# iorx62n register map
Registers from a debugger description file.
Registers are 8-bit, access not given, no defined reset value unless marked. A register's access mark holds for its fields unless they carry their own. Addresses are absolute; registers are grouped by the start of their names; lines under a group give offsets from that group; [hi:lo] are bit positions; {n}, {i} and the like mark numbered series; 'fields as' and 'values as' point back to an identical list; <NAME> marks a mode.

## SFR (part 1 of 3)
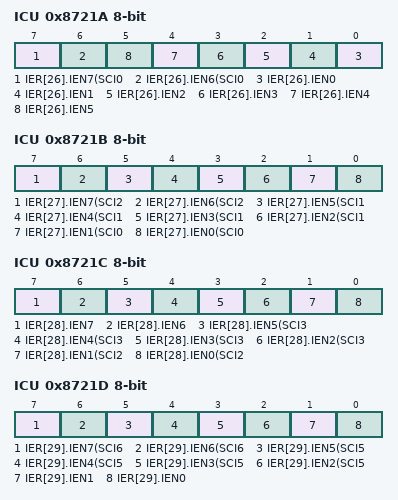
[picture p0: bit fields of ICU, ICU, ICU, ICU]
0x8721A ICU
  [7] IER[26].IEN7(SCI0,RXI0), [6] IER[26].IEN6(SCI0,ERI0), [n] IER[26].IEN{n} (n=0..5)
0x8721B ICU
  [7] IER[27].IEN7(SCI2,RXI2), [6] IER[27].IEN6(SCI2,ERI2), [5] IER[27].IEN5(SCI1,TEI1), [4] IER[27].IEN4(SCI1,TXI1), [3] IER[27].IEN3(SCI1,RXI1), [2] IER[27].IEN2(SCI1,ERI1), [1] IER[27].IEN1(SCI0,TEI0), [0] IER[27].IEN0(SCI0,TXI0)
0x8721C ICU
  [7] IER[28].IEN7, [6] IER[28].IEN6, [5] IER[28].IEN5(SCI3,TEI3), [4] IER[28].IEN4(SCI3,TXI3), [3] IER[28].IEN3(SCI3,RXI3), [2] IER[28].IEN2(SCI3,ERI3), [1] IER[28].IEN1(SCI2,TEI2), [0] IER[28].IEN0(SCI2,TXI2)
0x8721D ICU
  [7] IER[29].IEN7(SCI6,RXI6), [6] IER[29].IEN6(SCI6,ERI6), [5] IER[29].IEN5(SCI5,TEI5), [4] IER[29].IEN4(SCI5,TXI5), [3] IER[29].IEN3(SCI5,RXI5), [2] IER[29].IEN2(SCI5,ERI5), [1] IER[29].IEN1, [0] IER[29].IEN0
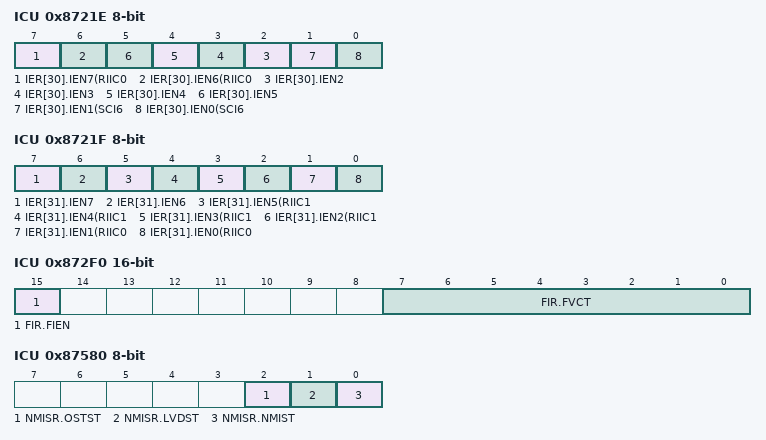
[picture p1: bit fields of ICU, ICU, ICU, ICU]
0x8721E ICU
  [7] IER[30].IEN7(RIIC0,ICRXI0), [6] IER[30].IEN6(RIIC0,ICEEI0), [n] IER[30].IEN{n} (n=2..5), [1] IER[30].IEN1(SCI6,TEI6), [0] IER[30].IEN0(SCI6,TXI6)
0x8721F ICU
  [7] IER[31].IEN7, [6] IER[31].IEN6, [5] IER[31].IEN5(RIIC1,ICTEI1), [4] IER[31].IEN4(RIIC1,ICTXI1), [3] IER[31].IEN3(RIIC1,ICRXI1), [2] IER[31].IEN2(RIIC1,ICEEI1), [1] IER[31].IEN1(RIIC0,ICTEI0), [0] IER[31].IEN0(RIIC0,ICTXI0)
0x872E0 ICU
  [0] SWINTR.SWINT
0x872F0 ICU 16-bit
  [15] FIR.FIEN, [7:0] FIR.FVCT
0x87300 ICU
  [3:0] IPR[0](BSC,BUSERR).IPR
0x87301 ICU
  [3:0] IPR[1](FCU,FIFERR).IPR
0x87302 ICU
  [3:0] IPR[2](FCU,FRDYI).IPR
0x87303 ICU
  [3:0] IPR[3](ICU,SWINT).IPR
0x87304 ICU
  [3:0] IPR[4](CMT0,CMI0).IPR
0x87305 ICU
  [3:0] IPR[5](CMT1,CMI1).IPR
0x87306 ICU
  [3:0] IPR[6](CMT2,CMI2).IPR
0x87307 ICU
  [3:0] IPR[7](CMT3,CMI3).IPR
0x87308 ICU
  [3:0] IPR[8](ETHER,EINT).IPR
0x87309 ICU
  [3:0] IPR[9].IPR
0x8730A ICU
  [3:0] IPR[10].IPR
0x8730B ICU
  [3:0] IPR[11].IPR
0x8730C ICU
  [3:0] IPR[12](USB0,D0FIFO0).IPR
0x8730D ICU
  [3:0] IPR[13](USB0,D1FIFO0).IPR
0x8730E ICU
  [3:0] IPR[14](USB0,USBI0).IPR
0x8730F ICU
  [3:0] IPR[15].IPR
0x87310 ICU
  [3:0] IPR[16](USB1,D0FIFO1).IPR
0x87311 ICU
  [3:0] IPR[17](USB1,D1FIFO1).IPR
0x87312 ICU
  [3:0] IPR[18](USB1,USBI1).IPR
0x87313 ICU
  [3:0] IPR[19].IPR
0x87314 ICU
  [3:0] IPR[20](RSPI0,SPEI0...).IPR
0x87315 ICU
  [3:0] IPR[21](RSPI1,SPEI1...).IPR
0x87316 ICU
  [3:0] IPR[22].IPR
0x87317 ICU
  [3:0] IPR[23].IPR
0x87318 ICU
  [3:0] IPR[24](CAN0,ERS0...).IPR
0x87319 ICU
  [3:0] IPR[25].IPR
0x8731A ICU
  [3:0] IPR[26].IPR
0x8731B ICU
  [3:0] IPR[27].IPR
0x8731C ICU
  [3:0] IPR[28].IPR
0x8731D ICU
  [3:0] IPR[29].IPR
0x8731E ICU
  [3:0] IPR[30](RTC,PRD).IPR
0x8731F ICU
  [3:0] IPR[31](RTC,CUP).IPR
0x87320 ICU
  [3:0] IPR[32](ICU,IRQ0).IPR
0x87321 ICU
  [3:0] IPR[33](ICU,IRQ1).IPR
0x87322 ICU
  [3:0] IPR[34](ICU,IRQ2).IPR
0x87323 ICU
  [3:0] IPR[35](ICU,IRQ3).IPR
0x87324 ICU
  [3:0] IPR[36](ICU,IRQ4).IPR
0x87325 ICU
  [3:0] IPR[37](ICU,IRQ5).IPR
0x87326 ICU
  [3:0] IPR[38](ICU,IRQ6).IPR
0x87327 ICU
  [3:0] IPR[39](ICU,IRQ7).IPR
0x87328 ICU
  [3:0] IPR[40](ICU,IRQ8).IPR
0x87329 ICU
  [3:0] IPR[41](ICU,IRQ9).IPR
0x8732A ICU
  [3:0] IPR[42](ICU,IRQ10).IPR
0x8732B ICU
  [3:0] IPR[43](ICU,IRQ11).IPR
0x8732C ICU
  [3:0] IPR[44](ICU,IRQ12).IPR
0x8732D ICU
  [3:0] IPR[45](ICU,IRQ13).IPR
0x8732E ICU
  [3:0] IPR[46](ICU,IRQ14).IPR
0x8732F ICU
  [3:0] IPR[47](ICU,IRQ15).IPR
0x87330 ICU
  [3:0] IPR[48].IPR
0x87331 ICU
  [3:0] IPR[49].IPR
0x87332 ICU
  [3:0] IPR[50].IPR
0x87333 ICU
  [3:0] IPR[51].IPR
0x87334 ICU
  [3:0] IPR[52].IPR
0x87335 ICU
  [3:0] IPR[53].IPR
0x87336 ICU
  [3:0] IPR[54].IPR
0x87337 ICU
  [3:0] IPR[55].IPR
0x87338 ICU
  [3:0] IPR[56].IPR
0x87339 ICU
  [3:0] IPR[57].IPR
0x8733A ICU
  [3:0] IPR[58](USB,USBR0).IPR
0x8733B ICU
  [3:0] IPR[59](USB,USBR1).IPR
0x8733C ICU
  [3:0] IPR[60](RTC,ALM).IPR
0x8733D ICU
  [3:0] IPR[61].IPR
0x8733E ICU
  [3:0] IPR[62].IPR
0x8733F ICU
  [3:0] IPR[63].IPR
0x87340 ICU
  [3:0] IPR[64](WDT,WOVI).IPR
0x87341 ICU
  [3:0] IPR[65].IPR
0x87342 ICU
  [3:0] IPR[66].IPR
0x87343 ICU
  [3:0] IPR[67].IPR
0x87344 ICU
  [3:0] IPR[68](AD0,ADI0).IPR
0x87345 ICU
  [3:0] IPR[69](AD1,ADI1).IPR
0x87346 ICU
  [3:0] IPR[70].IPR
0x87347 ICU
  [3:0] IPR[71].IPR
0x87348 ICU
  [3:0] IPR[72](S12AD,ADI).IPR
0x87349 ICU
  [3:0] IPR[73].IPR
0x8734A ICU
  [3:0] IPR[74].IPR
0x8734B ICU
  [3:0] IPR[75].IPR
0x8734C ICU
  [3:0] IPR[76].IPR
0x8734D ICU
  [3:0] IPR[77].IPR
0x8734E ICU
  [3:0] IPR[78].IPR
0x8734F ICU
  [3:0] IPR[79].IPR
0x87350 ICU
  [3:0] IPR[80].IPR
0x87351 ICU
  [3:0] IPR[81](MTU0,TGIA0...).IPR
0x87352 ICU
  [3:0] IPR[82](MTU0,TCIV0...).IPR
0x87353 ICU
  [3:0] IPR[83](MTU1,TGIA1...).IPR
0x87354 ICU
  [3:0] IPR[84](MTU1,TCIV1...).IPR
0x87355 ICU
  [3:0] IPR[85](MTU2,TGIA2...).IPR
0x87356 ICU
  [3:0] IPR[86](MTU2,TCIV2...).IPR
0x87357 ICU
  [3:0] IPR[87](MTU3,TGIA3...).IPR
0x87358 ICU
  [3:0] IPR[88](MTU3,TCIV3).IPR
0x87359 ICU
  [3:0] IPR[89](MTU4,TGIA4...).IPR
0x8735A ICU
  [3:0] IPR[90](MTU4,TCIV4).IPR
0x8735B ICU
  [3:0] IPR[91](MTU5,TGIU5...).IPR
0x8735C ICU
  [3:0] IPR[92](MTU6,TGIA6...).IPR
0x8735D ICU
  [3:0] IPR[93](MTU6,TCIV6...).IPR
0x8735E ICU
  [3:0] IPR[94](MTU7,TGIA7...).IPR
0x8735F ICU
  [3:0] IPR[95](MTU7,TCIV7...).IPR
0x87360 ICU
  [3:0] IPR[96](MTU8,TGIA8...).IPR
0x87361 ICU
  [3:0] IPR[97](MTU8,TCIV8...).IPR
0x87362 ICU
  [3:0] IPR[98](MTU9,TGIA9...).IPR
0x87363 ICU
  [3:0] IPR[99](MTU9,TCIV9).IPR
0x87364 ICU
  [3:0] IPR[100](MTU10,TGIA10...).IPR
0x87365 ICU
  [3:0] IPR[101](MTU10,TCIV10).IPR
0x87366 ICU
  [3:0] IPR[102](MTU11,TGIU11...).IPR
0x87367 ICU
  [3:0] IPR[103](POE,OEI1...).IPR
0x87368 ICU
  [3:0] IPR[104](TMR0,CMIA0...).IPR
0x87369 ICU
  [3:0] IPR[105](TMR1,CMIA1...).IPR
0x8736A ICU
  [3:0] IPR[106](TMR2,CMIA2...).IPR
0x8736B ICU
  [3:0] IPR[107](TMR3,CMIA3...).IPR
0x8736C ICU
  [3:0] IPR[108].IPR
0x8736D ICU
  [3:0] IPR[109].IPR
0x8736E ICU
  [3:0] IPR[110].IPR
0x8736F ICU
  [3:0] IPR[111].IPR
0x87370 ICU
  [3:0] IPR[112](DMAC,DMAC0I).IPR
0x87371 ICU
  [3:0] IPR[113](DMAC,DMAC1I).IPR
0x87372 ICU
  [3:0] IPR[114](DMAC,DMAC2I).IPR
0x87373 ICU
  [3:0] IPR[115](DMAC,DMAC3I).IPR
0x87374 ICU
  [3:0] IPR[116](EXDMAC,EXDMAC0I).IPR
0x87375 ICU
  [3:0] IPR[117](EXDMAC,EXDMAC1I).IPR
0x87376 ICU
  [3:0] IPR[118].IPR
0x87377 ICU
  [3:0] IPR[119].IPR
0x87378 ICU
  [3:0] IPR[120].IPR
0x87379 ICU
  [3:0] IPR[121].IPR
0x8737A ICU
  [3:0] IPR[122].IPR
0x8737B ICU
  [3:0] IPR[123].IPR
0x8737C ICU
  [3:0] IPR[124].IPR
0x8737D ICU
  [3:0] IPR[125].IPR
0x8737E ICU
  [3:0] IPR[126].IPR
0x8737F ICU
  [3:0] IPR[127].IPR
0x87380 ICU
  [3:0] IPR[128](SCI0,ERI0...).IPR
0x87381 ICU
  [3:0] IPR[129](SCI1,ERI1...).IPR
0x87382 ICU
  [3:0] IPR[130](SCI2,ERI2...).IPR
0x87383 ICU
  [3:0] IPR[131](SCI3,ERI3...).IPR
0x87384 ICU
  [3:0] IPR[132].IPR
0x87385 ICU
  [3:0] IPR[133](SCI5,ERI5...).IPR
0x87386 ICU
  [3:0] IPR[134](SCI6,ERI6...).IPR
0x87387 ICU
  [3:0] IPR[135].IPR
0x87388 ICU
  [3:0] IPR[136](RIIC0,ICEEI0).IPR
0x87389 ICU
  [3:0] IPR[137](RIIC0,ICRXI0).IPR
0x8738A ICU
  [3:0] IPR[138](RIIC0,ICTXI0).IPR
0x8738B ICU
  [3:0] IPR[139](RIIC0,ICTEI0).IPR
0x8738C ICU
  [3:0] IPR[140](RIIC1,ICEEI1).IPR
0x8738D ICU
  [3:0] IPR[141](RIIC1,ICRXI1).IPR
0x8738E ICU
  [3:0] IPR[142](RIIC1,ICTXI1).IPR
0x8738F ICU
  [3:0] IPR[143](RIIC1,ICTEI1).IPR
0x87500 ICU
  [3:2] IRQCR[0].IRQMD
0x87501 ICU
  [3:2] IRQCR[1].IRQMD
0x87502 ICU
  [3:2] IRQCR[2].IRQMD
0x87503 ICU
  [3:2] IRQCR[3].IRQMD
0x87504 ICU
  [3:2] IRQCR[4].IRQMD
0x87505 ICU
  [3:2] IRQCR[5].IRQMD
0x87506 ICU
  [3:2] IRQCR[6].IRQMD
0x87507 ICU
  [3:2] IRQCR[7].IRQMD
0x87508 ICU
  [3:2] IRQCR[8].IRQMD
0x87509 ICU
  [3:2] IRQCR[9].IRQMD
0x8750A ICU
  [3:2] IRQCR[10].IRQMD
0x8750B ICU
  [3:2] IRQCR[11].IRQMD
0x8750C ICU
  [3:2] IRQCR[12].IRQMD
0x8750D ICU
  [3:2] IRQCR[13].IRQMD
0x8750E ICU
  [3:2] IRQCR[14].IRQMD
0x8750F ICU
  [3:2] IRQCR[15].IRQMD
0x87580 ICU
  [2] NMISR.OSTST, [1] NMISR.LVDST, [0] NMISR.NMIST
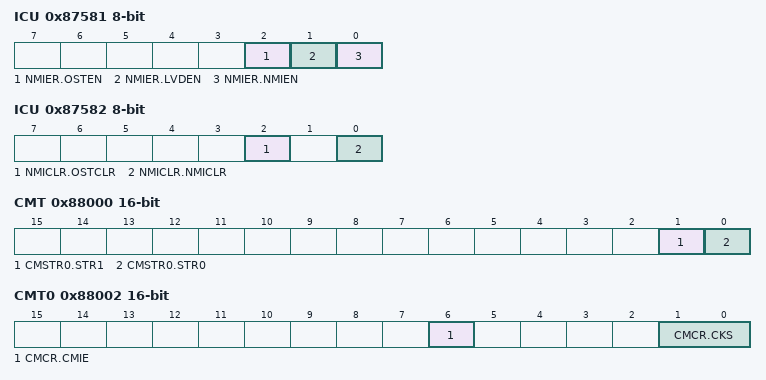
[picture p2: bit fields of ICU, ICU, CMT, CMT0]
0x87581 ICU
  [2] NMIER.OSTEN, [1] NMIER.LVDEN, [0] NMIER.NMIEN
0x87582 ICU
  [2] NMICLR.OSTCLR, [0] NMICLR.NMICLR
0x87583 ICU
  [3] NMICR.NMIMD
0x88000 CMT 16-bit
  [1] CMSTR0.STR1, [0] CMSTR0.STR0
0x88002 CMT0 16-bit
  [6] CMCR.CMIE, [1:0] CMCR.CKS
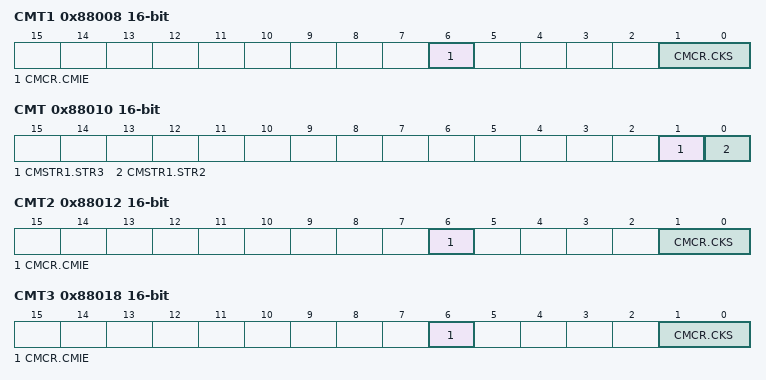
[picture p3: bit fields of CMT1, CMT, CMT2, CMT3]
0x88008 CMT1 16-bit
  [6] CMCR.CMIE, [1:0] CMCR.CKS
0x88010 CMT 16-bit
  [1] CMSTR1.STR3, [0] CMSTR1.STR2
0x88012 CMT2 16-bit
  [6] CMCR.CMIE, [1:0] CMCR.CKS
0x88018 CMT3 16-bit
  [6] CMCR.CMIE, [1:0] CMCR.CKS
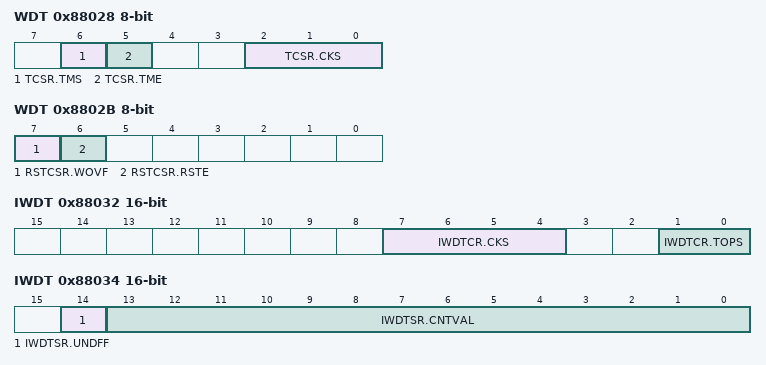
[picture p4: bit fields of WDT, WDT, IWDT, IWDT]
0x88028 WDT
  [6] TCSR.TMS, [5] TCSR.TME, [2:0] TCSR.CKS
0x8802B WDT
  [7] RSTCSR.WOVF, [6] RSTCSR.RSTE
0x88032 IWDT 16-bit
  [7:4] IWDTCR.CKS, [1:0] IWDTCR.TOPS
0x88034 IWDT 16-bit
  [14] IWDTSR.UNDFF, [13:0] IWDTSR.CNTVAL
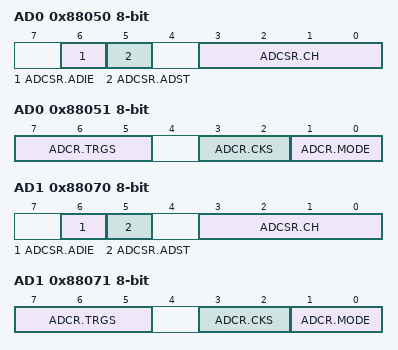
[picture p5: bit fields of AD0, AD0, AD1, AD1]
0x88050 AD0
  [6] ADCSR.ADIE, [5] ADCSR.ADST, [3:0] ADCSR.CH
0x88051 AD0
  [7:5] ADCR.TRGS, [3:2] ADCR.CKS, [1:0] ADCR.MODE
0x88052 AD0
  [7] ADDPR.DPSEL
0x8805F AD0
  [1:0] ADDIAGR.DIAG
0x88070 AD1
  [6] ADCSR.ADIE, [5] ADCSR.ADST, [3:0] ADCSR.CH
0x88071 AD1
  [7:5] ADCR.TRGS, [3:2] ADCR.CKS, [1:0] ADCR.MODE
0x88072 AD1
  [7] ADDPR.DPSEL
0x8807F AD1
  [1:0] ADDIAGR.DIAG
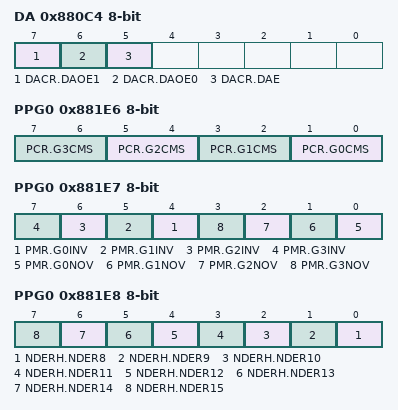
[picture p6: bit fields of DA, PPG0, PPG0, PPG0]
0x880C4 DA
  [7] DACR.DAOE1, [6] DACR.DAOE0, [5] DACR.DAE
0x880C5 DA
  [7] DADPR.DPSEL
0x881E6 PPG0
  [2n+1:2n] PCR.G{n}CMS (n=0..3)
0x881E7 PPG0
  [n+4] PMR.G{n}INV (n=0..3), [n] PMR.G{n}NOV (n=0..3)
0x881E8 PPG0
  [n-8] NDERH.NDER{n} (n=8..15)
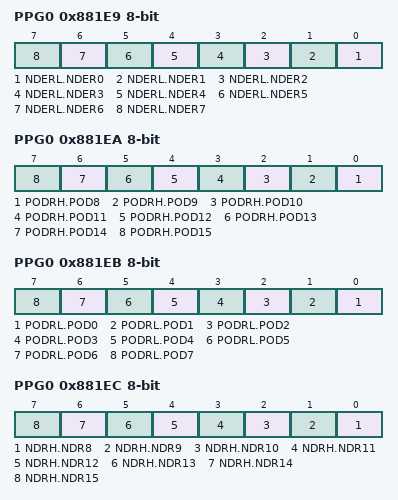
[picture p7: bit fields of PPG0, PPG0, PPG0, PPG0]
0x881E9 PPG0
  [n] NDERL.NDER{n} (n=0..7)
0x881EA PPG0
  [n-8] PODRH.POD{n} (n=8..15)
0x881EB PPG0
  [n] PODRL.POD{n} (n=0..7)
0x881EC PPG0
  [n-8] NDRH.NDR{n} (n=8..15)
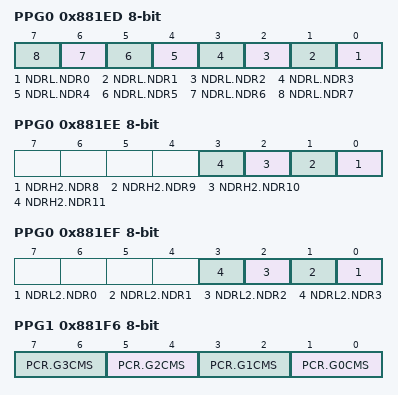
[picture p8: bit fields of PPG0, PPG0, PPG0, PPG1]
0x881ED PPG0
  [n] NDRL.NDR{n} (n=0..7)
0x881EE PPG0
  [n-8] NDRH2.NDR{n} (n=8..11)
0x881EF PPG0
  [n] NDRL2.NDR{n} (n=0..3)
0x881F0 PPG1
  [0] PTRSLR.PTRSL
0x881F6 PPG1
  [2n+1:2n] PCR.G{n}CMS (n=0..3)
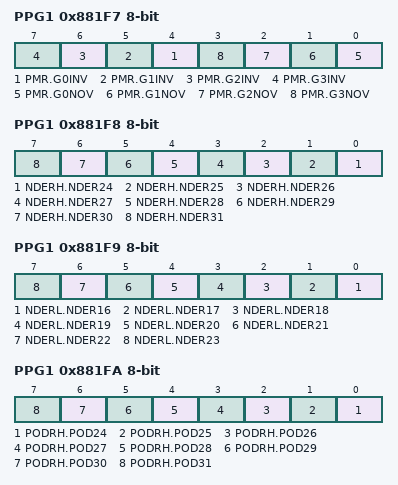
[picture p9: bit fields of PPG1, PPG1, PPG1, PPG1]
0x881F7 PPG1
  [n+4] PMR.G{n}INV (n=0..3), [n] PMR.G{n}NOV (n=0..3)
0x881F8 PPG1
  [n-24] NDERH.NDER{n} (n=24..31)
0x881F9 PPG1
  [n-16] NDERL.NDER{n} (n=16..23)
0x881FA PPG1
  [n-24] PODRH.POD{n} (n=24..31)
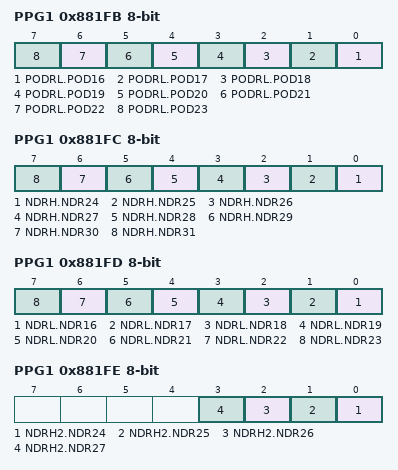
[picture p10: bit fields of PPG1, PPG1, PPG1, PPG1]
0x881FB PPG1
  [n-16] PODRL.POD{n} (n=16..23)
0x881FC PPG1
  [n-24] NDRH.NDR{n} (n=24..31)
0x881FD PPG1
  [n-16] NDRL.NDR{n} (n=16..23)
0x881FE PPG1
  [n-24] NDRH2.NDR{n} (n=24..27)
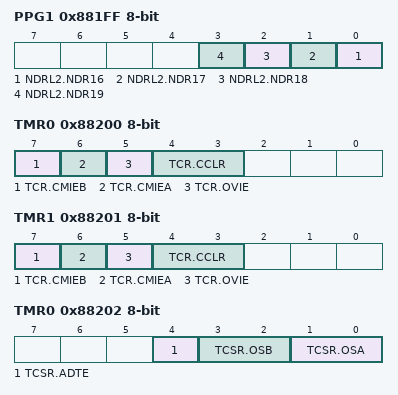
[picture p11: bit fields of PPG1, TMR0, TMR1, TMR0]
0x881FF PPG1
  [n-16] NDRL2.NDR{n} (n=16..19)
0x88200 TMR0
  [7] TCR.CMIEB, [6] TCR.CMIEA, [5] TCR.OVIE, [4:3] TCR.CCLR
0x88201 TMR1
  [7] TCR.CMIEB, [6] TCR.CMIEA, [5] TCR.OVIE, [4:3] TCR.CCLR
0x88202 TMR0
  [4] TCSR.ADTE, [3:2] TCSR.OSB, [1:0] TCSR.OSA
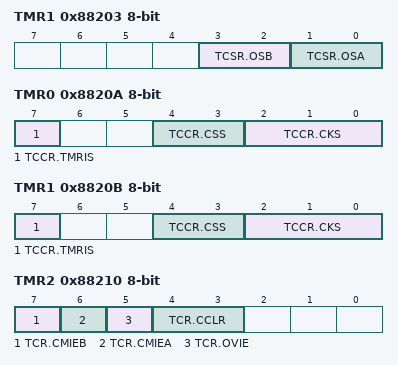
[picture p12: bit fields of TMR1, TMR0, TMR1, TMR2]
0x88203 TMR1
  [3:2] TCSR.OSB, [1:0] TCSR.OSA
0x8820A TMR0
  [7] TCCR.TMRIS, [4:3] TCCR.CSS, [2:0] TCCR.CKS
0x8820B TMR1
  [7] TCCR.TMRIS, [4:3] TCCR.CSS, [2:0] TCCR.CKS
0x88210 TMR2
  [7] TCR.CMIEB, [6] TCR.CMIEA, [5] TCR.OVIE, [4:3] TCR.CCLR
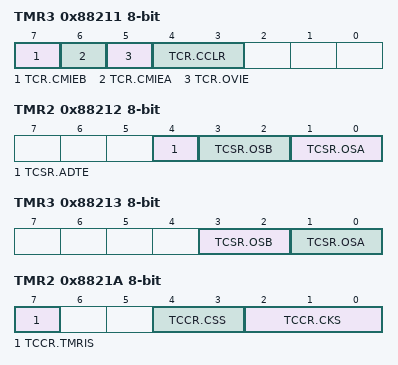
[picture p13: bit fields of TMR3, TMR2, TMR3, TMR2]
0x88211 TMR3
  [7] TCR.CMIEB, [6] TCR.CMIEA, [5] TCR.OVIE, [4:3] TCR.CCLR
0x88212 TMR2
  [4] TCSR.ADTE, [3:2] TCSR.OSB, [1:0] TCSR.OSA
0x88213 TMR3
  [3:2] TCSR.OSB, [1:0] TCSR.OSA
0x8821A TMR2
  [7] TCCR.TMRIS, [4:3] TCCR.CSS, [2:0] TCCR.CKS
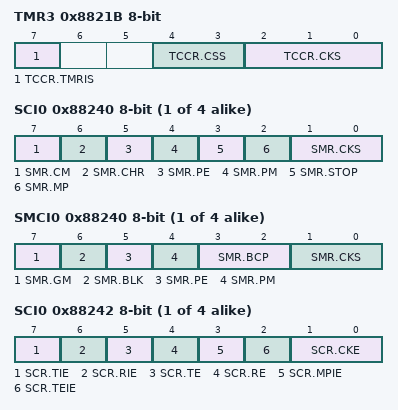
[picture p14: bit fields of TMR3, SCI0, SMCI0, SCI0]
0x8821B TMR3
  [7] TCCR.TMRIS, [4:3] TCCR.CSS, [2:0] TCCR.CKS
{0x88240+8i} SCI{i} (i=0..3)
  [7] SMR.CM, [6] SMR.CHR, [5] SMR.PE, [4] SMR.PM, [3] SMR.STOP, [2] SMR.MP, [1:0] SMR.CKS
{0x88240+8i} SMCI{i} (i=0..3)
  [7] SMR.GM, [6] SMR.BLK, [5] SMR.PE, [4] SMR.PM, [3:2] SMR.BCP, [1:0] SMR.CKS
{0x88242+8i} SCI{i} (i=0..3)
  [7] SCR.TIE, [6] SCR.RIE, [5] SCR.TE, [4] SCR.RE, [3] SCR.MPIE, [2] SCR.TEIE, [1:0] SCR.CKE
{0x88242+8i} SMCI{i} (i=0..3)
  [7] SCR.TIE, [6] SCR.RIE, [5] SCR.TE, [4] SCR.RE, [3] SCR.MPIE, [2] SCR.TEIE, [1:0] SCR.CKE
{0x88244+8i} SCI{i} (i=0..3)
  [7] SSR.TDRE, [6] SSR.RDRF, [5] SSR.ORER, [4] SSR.FER, [3] SSR.PER, [2] SSR.TEND, [1] SSR.MPB, [0] SSR.MPBT
{0x88244+8i} SMCI{i} (i=0..3)
  [7] SSR.TDRE, [6] SSR.RDRF, [5] SSR.ORER, [4] SSR.ERS, [3] SSR.PER, [2] SSR.TEND, [1] SSR.MPB, [0] SSR.MPBT
{0x88246+8i} SCI{i} (i=0..3)
  [7] SCMR.BCP2, [3] SCMR.SDIR, [2] SCMR.SINV, [0] SCMR.SMIF
{0x88246+8i} SMCI{i} (i=0..3)
  [7] SCMR.BCP2, [3] SCMR.SDIR, [2] SCMR.SINV, [0] SCMR.SMIF
{0x88247+8i} SCI{i} (i=0..3)
  [4] SEMR.ABCS, [0] SEMR.ACS0
0x88268 SCI5
  fields as SCI0
0x88268 SMCI5
  fields as SMCI0
0x8826A SCI5
  [7] SCR.TIE, [6] SCR.RIE, [5] SCR.TE, [4] SCR.RE, [3] SCR.MPIE, [2] SCR.TEIE, [1:0] SCR.CKE
0x8826A SMCI5
  [7] SCR.TIE, [6] SCR.RIE, [5] SCR.TE, [4] SCR.RE, [3] SCR.MPIE, [2] SCR.TEIE, [1:0] SCR.CKE
0x8826C SCI5
  [7] SSR.TDRE, [6] SSR.RDRF, [5] SSR.ORER, [4] SSR.FER, [3] SSR.PER, [2] SSR.TEND, [1] SSR.MPB, [0] SSR.MPBT
0x8826C SMCI5
  [7] SSR.TDRE, [6] SSR.RDRF, [5] SSR.ORER, [4] SSR.ERS, [3] SSR.PER, [2] SSR.TEND, [1] SSR.MPB, [0] SSR.MPBT
0x8826E SCI5
  [7] SCMR.BCP2, [3] SCMR.SDIR, [2] SCMR.SINV, [0] SCMR.SMIF
0x8826E SMCI5
  [7] SCMR.BCP2, [3] SCMR.SDIR, [2] SCMR.SINV, [0] SCMR.SMIF
0x8826F SCI5
  [4] SEMR.ABCS, [0] SEMR.ACS0
0x88270 SCI6
  fields as SCI0
0x88270 SMCI6
  fields as SMCI0
0x88272 SCI6
  [7] SCR.TIE, [6] SCR.RIE, [5] SCR.TE, [4] SCR.RE, [3] SCR.MPIE, [2] SCR.TEIE, [1:0] SCR.CKE
0x88272 SMCI6
  [7] SCR.TIE, [6] SCR.RIE, [5] SCR.TE, [4] SCR.RE, [3] SCR.MPIE, [2] SCR.TEIE, [1:0] SCR.CKE
0x88274 SCI6
  [7] SSR.TDRE, [6] SSR.RDRF, [5] SSR.ORER, [4] SSR.FER, [3] SSR.PER, [2] SSR.TEND, [1] SSR.MPB, [0] SSR.MPBT
0x88274 SMCI6
  [7] SSR.TDRE, [6] SSR.RDRF, [5] SSR.ORER, [4] SSR.ERS, [3] SSR.PER, [2] SSR.TEND, [1] SSR.MPB, [0] SSR.MPBT
0x88276 SCI6
  [7] SCMR.BCP2, [3] SCMR.SDIR, [2] SCMR.SINV, [0] SCMR.SMIF
0x88276 SMCI6
  [7] SCMR.BCP2, [3] SCMR.SDIR, [2] SCMR.SINV, [0] SCMR.SMIF
0x88277 SCI6
  [4] SEMR.ABCS, [0] SEMR.ACS0
0x88280 CRC
  [7] CRCCR.DORCLR, [2] CRCCR.LMS, [1:0] CRCCR.GPS
0x88300 RIIC0
  [7] ICCR1.ICE, [6] ICCR1.IICRST, [5] ICCR1.CLO, [4] ICCR1.SOWP, [3] ICCR1.SCLO, [2] ICCR1.SDAO, [1] ICCR1.SCLI, [0] ICCR1.SDAI
0x88301 RIIC0
  [7] ICCR2.BBSY, [6] ICCR2.MST, [5] ICCR2.TRS, [3] ICCR2.SP, [2] ICCR2.RS, [1] ICCR2.ST
0x88302 RIIC0
  [7] ICMR1.MTWP, [6:4] ICMR1.CKS, [3] ICMR1.BCWP, [2:0] ICMR1.BC
0x88303 RIIC0
  [7] ICMR2.DLCS, [6:4] ICMR2.SDDL, [2] ICMR2.TMOH, [1] ICMR2.TMOL, [0] ICMR2.TMOS
0x88304 RIIC0
  [7] ICMR3.SMBS, [6] ICMR3.WAIT, [5] ICMR3.RDRFS, [4] ICMR3.ACKWP, [3] ICMR3.ACKBT, [2] ICMR3.ACKBR, [1:0] ICMR3.NF
0x88305 RIIC0
  [7] ICFER.FMPE, [6] ICFER.SCLE, [5] ICFER.NFE, [4] ICFER.NACKE, [3] ICFER.SALE, [2] ICFER.NALE, [1] ICFER.MALE, [0] ICFER.TMOE
0x88306 RIIC0
  [7] ICSER.HOAE, [5] ICSER.DIDE, [3] ICSER.GCAE, [2] ICSER.SAR2E, [1] ICSER.SAR1E, [0] ICSER.SAR0E
0x88307 RIIC0
  [7] ICIER.TIE, [6] ICIER.TEIE, [5] ICIER.RIE, [4] ICIER.NAKIE, [3] ICIER.SPIE, [2] ICIER.STIE, [1] ICIER.ALIE, [0] ICIER.TMOIE
0x88308 RIIC0
  [7] ICSR1.HOA, [5] ICSR1.DID, [3] ICSR1.GCA, [2] ICSR1.AAS2, [1] ICSR1.AAS1, [0] ICSR1.AAS0
0x88309 RIIC0
  [7] ICSR2.TDRE, [6] ICSR2.TEND, [5] ICSR2.RDRF, [4] ICSR2.NACKF, [3] ICSR2.STOP, [2] ICSR2.START, [1] ICSR2.AL, [0] ICSR2.TMOF
0x8830A RIIC0
  [7:1] SARL0.SVA, [0] SARL0.SVA0
0x8830B RIIC0
  [2:1] SARU0.SVA, [0] SARU0.FS
0x8830C RIIC0
  [7:1] SARL1.SVA, [0] SARL1.SVA0
0x8830D RIIC0
  [2:1] SARU1.SVA, [0] SARU1.FS
0x8830E RIIC0
  [7:1] SARL2.SVA, [0] SARL2.SVA0
0x8830F RIIC0
  [2:1] SARU2.SVA, [0] SARU2.FS
0x88310 RIIC0
  [4:0] ICBRL.BRL
0x88311 RIIC0
  [4:0] ICBRH.BRH
0x88320 RIIC1
  fields as RIIC0
0x88321 RIIC1
  [7] ICCR2.BBSY, [6] ICCR2.MST, [5] ICCR2.TRS, [3] ICCR2.SP, [2] ICCR2.RS, [1] ICCR2.ST
0x88322 RIIC1
  [7] ICMR1.MTWP, [6:4] ICMR1.CKS, [3] ICMR1.BCWP, [2:0] ICMR1.BC
0x88323 RIIC1
  [7] ICMR2.DLCS, [6:4] ICMR2.SDDL, [2] ICMR2.TMOH, [1] ICMR2.TMOL, [0] ICMR2.TMOS
0x88324 RIIC1
  [7] ICMR3.SMBS, [6] ICMR3.WAIT, [5] ICMR3.RDRFS, [4] ICMR3.ACKWP, [3] ICMR3.ACKBT, [2] ICMR3.ACKBR, [1:0] ICMR3.NF
0x88325 RIIC1
  [7] ICFER.FMPE, [6] ICFER.SCLE, [5] ICFER.NFE, [4] ICFER.NACKE, [3] ICFER.SALE, [2] ICFER.NALE, [1] ICFER.MALE, [0] ICFER.TMOE
0x88326 RIIC1
  [7] ICSER.HOAE, [5] ICSER.DIDE, [3] ICSER.GCAE, [2] ICSER.SAR2E, [1] ICSER.SAR1E, [0] ICSER.SAR0E
0x88327 RIIC1
  [7] ICIER.TIE, [6] ICIER.TEIE, [5] ICIER.RIE, [4] ICIER.NAKIE, [3] ICIER.SPIE, [2] ICIER.STIE, [1] ICIER.ALIE, [0] ICIER.TMOIE
0x88328 RIIC1
  [7] ICSR1.HOA, [5] ICSR1.DID, [3] ICSR1.GCA, [2] ICSR1.AAS2, [1] ICSR1.AAS1, [0] ICSR1.AAS0
0x88329 RIIC1
  [7] ICSR2.TDRE, [6] ICSR2.TEND, [5] ICSR2.RDRF, [4] ICSR2.NACKF, [3] ICSR2.STOP, [2] ICSR2.START, [1] ICSR2.AL, [0] ICSR2.TMOF
0x8832A RIIC1
  [7:1] SARL0.SVA, [0] SARL0.SVA0
0x8832B RIIC1
  [2:1] SARU0.SVA, [0] SARU0.FS
0x8832C RIIC1
  [7:1] SARL1.SVA, [0] SARL1.SVA0
0x8832D RIIC1
  [2:1] SARU1.SVA, [0] SARU1.FS
0x8832E RIIC1
  [7:1] SARL2.SVA, [0] SARL2.SVA0
0x8832F RIIC1
  [2:1] SARU2.SVA, [0] SARU2.FS
0x88330 RIIC1
  [4:0] ICBRL.BRL
0x88331 RIIC1
  [4:0] ICBRH.BRH
0x88380 RSPI0
  [7] SPCR.SPRIE, [6] SPCR.SPE, [5] SPCR.SPTIE, [4] SPCR.SPEIE, [3] SPCR.MSTR, [2] SPCR.MODFEN, [1] SPCR.TXMD, [0] SPCR.SPMS
0x88381 RSPI0
  [n] SSLP.SSLP{n} (n=0..3)
0x88382 RSPI0
  [5] SPPCR.MOIFE, [4] SPPCR.MOIFV, [2] SPPCR.SPOM, [1] SPPCR.SPLP2, [0] SPPCR.SPLP
0x88383 RSPI0
  [7] SPSR.SPRF, [5] SPSR.SPTEF, [3] SPSR.PERF, [2] SPSR.MODF, [1] SPSR.IDLNF, [0] SPSR.OVRF
0x88384 RSPI0 32-bit
  [31:16] SPDR.H
0x88388 RSPI0
  [2:0] SPSCR.SPSLN
0x88389 RSPI0
  [6:4] SPSSR.SPECM, [2:0] SPSSR.SPCP
0x8838B RSPI0
  [5] SPDCR.SPLW, [4] SPDCR.SPRDTD, [3:2] SPDCR.SLSEL, [1:0] SPDCR.SPFC
0x8838C RSPI0
  [2:0] SPCKD.SCKDL
0x8838D RSPI0
  [2:0] SSLND.SLNDL
0x8838E RSPI0
  [2:0] SPND.SPNDL
0x8838F RSPI0
  [3] SPCR2.PTE, [2] SPCR2.SPIIE, [1] SPCR2.SPOE, [0] SPCR2.SPPE
0x88390 RSPI0 16-bit
  [15] SPCMD0.SCKDEN, [14] SPCMD0.SLNDEN, [13] SPCMD0.SPNDEN, [12] SPCMD0.LSBF, [11:8] SPCMD0.SPB, [7] SPCMD0.SSLKP, [6:4] SPCMD0.SSLA, [3:2] SPCMD0.BRDV, [1] SPCMD0.CPOL, [0] SPCMD0.CPHA
0x88392 RSPI0 16-bit
  [15] SPCMD1.SCKDEN, [14] SPCMD1.SLNDEN, [13] SPCMD1.SPNDEN, [12] SPCMD1.LSBF, [11:8] SPCMD1.SPB, [7] SPCMD1.SSLKP, [6:4] SPCMD1.SSLA, [3:2] SPCMD1.BRDV, [1] SPCMD1.CPOL, [0] SPCMD1.CPHA
0x88394 RSPI0 16-bit
  [15] SPCMD2.SCKDEN, [14] SPCMD2.SLNDEN, [13] SPCMD2.SPNDEN, [12] SPCMD2.LSBF, [11:8] SPCMD2.SPB, [7] SPCMD2.SSLKP, [6:4] SPCMD2.SSLA, [3:2] SPCMD2.BRDV, [1] SPCMD2.CPOL, [0] SPCMD2.CPHA
0x88396 RSPI0 16-bit
  [15] SPCMD3.SCKDEN, [14] SPCMD3.SLNDEN, [13] SPCMD3.SPNDEN, [12] SPCMD3.LSBF, [11:8] SPCMD3.SPB, [7] SPCMD3.SSLKP, [6:4] SPCMD3.SSLA, [3:2] SPCMD3.BRDV, [1] SPCMD3.CPOL, [0] SPCMD3.CPHA
0x88398 RSPI0 16-bit
  [15] SPCMD4.SCKDEN, [14] SPCMD4.SLNDEN, [13] SPCMD4.SPNDEN, [12] SPCMD4.LSBF, [11:8] SPCMD4.SPB, [7] SPCMD4.SSLKP, [6:4] SPCMD4.SSLA, [3:2] SPCMD4.BRDV, [1] SPCMD4.CPOL, [0] SPCMD4.CPHA
0x8839A RSPI0 16-bit
  [15] SPCMD5.SCKDEN, [14] SPCMD5.SLNDEN, [13] SPCMD5.SPNDEN, [12] SPCMD5.LSBF, [11:8] SPCMD5.SPB, [7] SPCMD5.SSLKP, [6:4] SPCMD5.SSLA, [3:2] SPCMD5.BRDV, [1] SPCMD5.CPOL, [0] SPCMD5.CPHA
0x8839C RSPI0 16-bit
  [15] SPCMD6.SCKDEN, [14] SPCMD6.SLNDEN, [13] SPCMD6.SPNDEN, [12] SPCMD6.LSBF, [11:8] SPCMD6.SPB, [7] SPCMD6.SSLKP, [6:4] SPCMD6.SSLA, [3:2] SPCMD6.BRDV, [1] SPCMD6.CPOL, [0] SPCMD6.CPHA
0x8839E RSPI0 16-bit
  [15] SPCMD7.SCKDEN, [14] SPCMD7.SLNDEN, [13] SPCMD7.SPNDEN, [12] SPCMD7.LSBF, [11:8] SPCMD7.SPB, [7] SPCMD7.SSLKP, [6:4] SPCMD7.SSLA, [3:2] SPCMD7.BRDV, [1] SPCMD7.CPOL, [0] SPCMD7.CPHA
0x883A0 RSPI1
  fields as RSPI0
0x883A1 RSPI1
  [n] SSLP.SSLP{n} (n=0..3)
0x883A2 RSPI1
  [5] SPPCR.MOIFE, [4] SPPCR.MOIFV, [2] SPPCR.SPOM, [1] SPPCR.SPLP2, [0] SPPCR.SPLP
0x883A3 RSPI1
  [7] SPSR.SPRF, [5] SPSR.SPTEF, [3] SPSR.PERF, [2] SPSR.MODF, [1] SPSR.IDLNF, [0] SPSR.OVRF
0x883A4 RSPI1 32-bit
  [31:16] SPDR.H
0x883A8 RSPI1
  [2:0] SPSCR.SPSLN
0x883A9 RSPI1
  [6:4] SPSSR.SPECM, [2:0] SPSSR.SPCP
0x883AB RSPI1
  [5] SPDCR.SPLW, [4] SPDCR.SPRDTD, [3:2] SPDCR.SLSEL, [1:0] SPDCR.SPFC
0x883AC RSPI1
  [2:0] SPCKD.SCKDL
0x883AD RSPI1
  [2:0] SSLND.SLNDL
0x883AE RSPI1
  [2:0] SPND.SPNDL
0x883AF RSPI1
  [3] SPCR2.PTE, [2] SPCR2.SPIIE, [1] SPCR2.SPOE, [0] SPCR2.SPPE
0x883B0 RSPI1 16-bit
  [15] SPCMD0.SCKDEN, [14] SPCMD0.SLNDEN, [13] SPCMD0.SPNDEN, [12] SPCMD0.LSBF, [11:8] SPCMD0.SPB, [7] SPCMD0.SSLKP, [6:4] SPCMD0.SSLA, [3:2] SPCMD0.BRDV, [1] SPCMD0.CPOL, [0] SPCMD0.CPHA
0x883B2 RSPI1 16-bit
  [15] SPCMD1.SCKDEN, [14] SPCMD1.SLNDEN, [13] SPCMD1.SPNDEN, [12] SPCMD1.LSBF, [11:8] SPCMD1.SPB, [7] SPCMD1.SSLKP, [6:4] SPCMD1.SSLA, [3:2] SPCMD1.BRDV, [1] SPCMD1.CPOL, [0] SPCMD1.CPHA
0x883B4 RSPI1 16-bit
  [15] SPCMD2.SCKDEN, [14] SPCMD2.SLNDEN, [13] SPCMD2.SPNDEN, [12] SPCMD2.LSBF, [11:8] SPCMD2.SPB, [7] SPCMD2.SSLKP, [6:4] SPCMD2.SSLA, [3:2] SPCMD2.BRDV, [1] SPCMD2.CPOL, [0] SPCMD2.CPHA
0x883B6 RSPI1 16-bit
  [15] SPCMD3.SCKDEN, [14] SPCMD3.SLNDEN, [13] SPCMD3.SPNDEN, [12] SPCMD3.LSBF, [11:8] SPCMD3.SPB, [7] SPCMD3.SSLKP, [6:4] SPCMD3.SSLA, [3:2] SPCMD3.BRDV, [1] SPCMD3.CPOL, [0] SPCMD3.CPHA
0x883B8 RSPI1 16-bit
  [15] SPCMD4.SCKDEN, [14] SPCMD4.SLNDEN, [13] SPCMD4.SPNDEN, [12] SPCMD4.LSBF, [11:8] SPCMD4.SPB, [7] SPCMD4.SSLKP, [6:4] SPCMD4.SSLA, [3:2] SPCMD4.BRDV, [1] SPCMD4.CPOL, [0] SPCMD4.CPHA
0x883BA RSPI1 16-bit
  [15] SPCMD5.SCKDEN, [14] SPCMD5.SLNDEN, [13] SPCMD5.SPNDEN, [12] SPCMD5.LSBF, [11:8] SPCMD5.SPB, [7] SPCMD5.SSLKP, [6:4] SPCMD5.SSLA, [3:2] SPCMD5.BRDV, [1] SPCMD5.CPOL, [0] SPCMD5.CPHA
0x883BC RSPI1 16-bit
  [15] SPCMD6.SCKDEN, [14] SPCMD6.SLNDEN, [13] SPCMD6.SPNDEN, [12] SPCMD6.LSBF, [11:8] SPCMD6.SPB, [7] SPCMD6.SSLKP, [6:4] SPCMD6.SSLA, [3:2] SPCMD6.BRDV, [1] SPCMD6.CPOL, [0] SPCMD6.CPHA
0x883BE RSPI1 16-bit
  [15] SPCMD7.SCKDEN, [14] SPCMD7.SLNDEN, [13] SPCMD7.SPNDEN, [12] SPCMD7.LSBF, [11:8] SPCMD7.SPB, [7] SPCMD7.SSLKP, [6:4] SPCMD7.SSLA, [3:2] SPCMD7.BRDV, [1] SPCMD7.CPOL, [0] SPCMD7.CPHA
0x88600 MTU3
  [7:5] TCR.CCLR, [4:3] TCR.CKEG, [2:0] TCR.TPSC
0x88601 MTU4
  [7:5] TCR.CCLR, [4:3] TCR.CKEG, [2:0] TCR.TPSC
0x88602 MTU3
  [5] TMDR.BFB, [4] TMDR.BFA, [3:0] TMDR.MD
0x88603 MTU4
  [5] TMDR.BFB, [4] TMDR.BFA, [3:0] TMDR.MD
0x88604 MTU3
  [7:4] TIORH.IOB, [3:0] TIORH.IOA
0x88605 MTU3
  [7:4] TIORL.IOD, [3:0] TIORL.IOC
0x88606 MTU4
  [7:4] TIORH.IOB, [3:0] TIORH.IOA
0x88607 MTU4
  [7:4] TIORL.IOD, [3:0] TIORL.IOC
0x88608 MTU3
  [7] TIER.TTGE, [4] TIER.TCIEV, [3] TIER.TGIED, [2] TIER.TGIEC, [1] TIER.TGIEB, [0] TIER.TGIEA
0x88609 MTU4
  [7] TIER.TTGE, [6] TIER.TTGE2, [4] TIER.TCIEV, [3] TIER.TGIED, [2] TIER.TGIEC, [1] TIER.TGIEB, [0] TIER.TGIEA
0x8860A MTUA
  [5] TOER.OE4D, [4] TOER.OE4C, [3] TOER.OE3D, [2] TOER.OE4B, [1] TOER.OE4A, [0] TOER.OE3B
0x8860D MTUA
  [6] TGCR.BDC, [5] TGCR.N, [4] TGCR.P, [3] TGCR.FB, [2] TGCR.WF, [1] TGCR.VF, [0] TGCR.UF
0x8860E MTUA
  [6] TOCR1.PSYE, [3] TOCR1.TOCL, [2] TOCR1.TOCS, [1] TOCR1.OLSN, [0] TOCR1.OLSP
0x8860F MTUA
  [7:6] TOCR2.BF, [5] TOCR2.OLS3N, [4] TOCR2.OLS3P, [3] TOCR2.OLS2N, [2] TOCR2.OLS2P, [1] TOCR2.OLS1N, [0] TOCR2.OLS1P
0x8862C MTU3
  [7] TSR.TCFD
0x8862D MTU4
  [7] TSR.TCFD
0x88630 MTUA
  [7] TITCR.T3AEN, [6:4] TITCR.T3ACOR, [3] TITCR.T4VEN, [2:0] TITCR.T4VCOR
0x88631 MTUA
  [6:4] TITCNT.T3ACNT, [2:0] TITCNT.T4VCNT
0x88632 MTUA
  [1:0] TBTER.BTE
0x88634 MTUA
  [0] TDER.TDER
0x88636 MTUA
  [5] TOLBR.OLS3N, [4] TOLBR.OLS3P, [3] TOLBR.OLS2N, [2] TOLBR.OLS2P, [1] TOLBR.OLS1N, [0] TOLBR.OLS1P
0x88638 MTU3
  [1] TBTM.TTSB, [0] TBTM.TTSA
0x88639 MTU4
  [1] TBTM.TTSB, [0] TBTM.TTSA
0x88640 MTU4 16-bit
  [15:14] TADCR.BF, [7] TADCR.UT4AE, [6] TADCR.DT4AE, [5] TADCR.UT4BE, [4] TADCR.DT4BE, [3] TADCR.ITA3AE, [2] TADCR.ITA4VE, [1] TADCR.ITB3AE, [0] TADCR.ITB4VE
0x88660 MTUA
  [7] TWCR.CCE, [0] TWCR.WRE
0x88680 MTUA
  [7] TSTR.CST4, [6] TSTR.CST3, [2] TSTR.CST2, [1] TSTR.CST1, [0] TSTR.CST0
0x88681 MTUA
  [7] TSYR.SYNC4, [6] TSYR.SYNC3, [2] TSYR.SYNC2, [1] TSYR.SYNC1, [0] TSYR.SYNC0
0x88684 MTUA
  [0] TRWER.RWE
0x88700 MTU0
  [7:5] TCR.CCLR, [4:3] TCR.CKEG, [2:0] TCR.TPSC
0x88701 MTU0
  [6] TMDR.BFE, [5] TMDR.BFB, [4] TMDR.BFA, [3:0] TMDR.MD
0x88702 MTU0
  [7:4] TIORH.IOB, [3:0] TIORH.IOA
0x88703 MTU0
  [7:4] TIORL.IOD, [3:0] TIORL.IOC
0x88704 MTU0
  [7] TIER.TTGE, [4] TIER.TCIEV, [3] TIER.TGIED, [2] TIER.TGIEC, [1] TIER.TGIEB, [0] TIER.TGIEA
0x88724 MTU0
  [1] TIER2.TGIEF, [0] TIER2.TGIEE
0x88726 MTU0
  [2] TBTM.TTSE, [1] TBTM.TTSB, [0] TBTM.TTSA
0x88780 MTU1
  [6:5] TCR.CCLR, [4:3] TCR.CKEG, [2:0] TCR.TPSC
0x88781 MTU1
  [3:0] TMDR.MD
0x88782 MTU1
  [7:4] TIOR.IOB, [3:0] TIOR.IOA
0x88784 MTU1
  [7] TIER.TTGE, [5] TIER.TCIEU, [4] TIER.TCIEV, [1] TIER.TGIEB, [0] TIER.TGIEA
0x88785 MTU1
  [7] TSR.TCFD
0x88790 MTU1
  [3] TICCR.I2BE, [2] TICCR.I2AE, [1] TICCR.I1BE, [0] TICCR.I1AE
0x88800 MTU2
  [6:5] TCR.CCLR, [4:3] TCR.CKEG, [2:0] TCR.TPSC
0x88801 MTU2
  [3:0] TMDR.MD
0x88802 MTU2
  [7:4] TIOR.IOB, [3:0] TIOR.IOA
0x88804 MTU2
  [7] TIER.TTGE, [5] TIER.TCIEU, [4] TIER.TCIEV, [1] TIER.TGIEB, [0] TIER.TGIEA
0x88805 MTU2
  [7] TSR.TCFD
0x88884 MTU5
  [1:0] TCRU.TPSC
0x88886 MTU5
  [4:0] TIORU.IOC
0x88894 MTU5
  [1:0] TCRV.TPSC
0x88896 MTU5
  [4:0] TIORV.IOC
0x888A4 MTU5
  [1:0] TCRW.TPSC
0x888A6 MTU5
  [4:0] TIORW.IOC
0x888B2 MTU5
  [2] TIER.TGIE5U, [1] TIER.TGIE5V, [0] TIER.TGIE5W
0x888B4 MTU5
  [2] TSTR.CSTU5, [1] TSTR.CSTV5, [0] TSTR.CSTW5
0x888B6 MTU5
  [2] TCNTCMPCLR.CMPCLR5U, [1] TCNTCMPCLR.CMPCLR5V, [0] TCNTCMPCLR.CMPCLR5W
0x88900 POE 16-bit
  [n+12] ICSR1.POE{n}F (n=0..3), [8] ICSR1.PIE1, [2n+1:2n] ICSR1.POE{n}M (n=0..3)
0x88902 POE 16-bit
  [15] OCSR1.OSF1, [9] OCSR1.OCE1, [8] OCSR1.OIE1
0x88904 POE 16-bit
  [n+8] ICSR2.POE{n}F (n=4..7), [8] ICSR2.PIE2, [2n-7:2n-8] ICSR2.POE{n}M (n=4..7)
0x88906 POE 16-bit
  [15] OCSR2.OSF2, [9] OCSR2.OCE2, [8] OCSR2.OIE2
0x88908 POE 16-bit
  [12] ICSR3.POE8F, [9] ICSR3.POE8E, [8] ICSR3.PIE3, [1:0] ICSR3.POE8M
0x8890A POE
  [3] SPOER.CH6HIZ, [2] SPOER.CH910HIZ, [1] SPOER.CH0HIZ, [0] SPOER.CH34HIZ
0x8890B POE
  [n] POECR1.PE{n}ZE (n=0..7)
0x8890C POE 16-bit
  [14] POECR2.P1CZEA, [13] POECR2.P2CZEA, [12] POECR2.P3CZEA, [10] POECR2.P1CZEB, [9] POECR2.P2CZEB, [8] POECR2.P3CZEB, [6] POECR2.P4CZE, [5] POECR2.P5CZE, [4] POECR2.P6CZE
0x8890E POE 16-bit
  [12] ICSR4.POE9F, [9] ICSR4.POE9E, [8] ICSR4.PIE4, [1:0] ICSR4.POE9M
0x88A00 MTU9
  [7:5] TCR.CCLR, [4:3] TCR.CKEG, [2:0] TCR.TPSC
0x88A01 MTU10
  [7:5] TCR.CCLR, [4:3] TCR.CKEG, [2:0] TCR.TPSC
0x88A02 MTU9
  [5] TMDR.BFB, [4] TMDR.BFA, [3:0] TMDR.MD
0x88A03 MTU10
  [5] TMDR.BFB, [4] TMDR.BFA, [3:0] TMDR.MD
0x88A04 MTU9
  [7:4] TIORH.IOB, [3:0] TIORH.IOA
0x88A05 MTU9
  [7:4] TIORL.IOD, [3:0] TIORL.IOC
0x88A06 MTU10
  [7:4] TIORH.IOB, [3:0] TIORH.IOA
0x88A07 MTU10
  [7:4] TIORL.IOD, [3:0] TIORL.IOC
0x88A08 MTU9
  [7] TIER.TTGE, [4] TIER.TCIEV, [3] TIER.TGIED, [2] TIER.TGIEC, [1] TIER.TGIEB, [0] TIER.TGIEA
0x88A09 MTU10
  [7] TIER.TTGE, [6] TIER.TTGE2, [4] TIER.TCIEV, [3] TIER.TGIED, [2] TIER.TGIEC, [1] TIER.TGIEB, [0] TIER.TGIEA
0x88A0A MTUB
  fields as MTUA
0x88A0D MTUB
  [6] TGCR.BDC, [5] TGCR.N, [4] TGCR.P, [3] TGCR.FB, [2] TGCR.WF, [1] TGCR.VF, [0] TGCR.UF
0x88A0E MTUB
  [6] TOCR1.PSYE, [3] TOCR1.TOCL, [2] TOCR1.TOCS, [1] TOCR1.OLSN, [0] TOCR1.OLSP
0x88A0F MTUB
  [7:6] TOCR2.BF, [5] TOCR2.OLS3N, [4] TOCR2.OLS3P, [3] TOCR2.OLS2N, [2] TOCR2.OLS2P, [1] TOCR2.OLS1N, [0] TOCR2.OLS1P
0x88A2C MTU9
  [7] TSR.TCFD
0x88A2D MTU10
  [7] TSR.TCFD
0x88A30 MTUB
  [7] TITCR.T3AEN, [6:4] TITCR.T3ACOR, [3] TITCR.T4VEN, [2:0] TITCR.T4VCOR
0x88A31 MTUB
  [6:4] TITCNT.T3ACNT, [2:0] TITCNT.T4VCNT
0x88A32 MTUB
  [1:0] TBTER.BTE
0x88A34 MTUB
  [0] TDER.TDER
0x88A36 MTUB
  [5] TOLBR.OLS3N, [4] TOLBR.OLS3P, [3] TOLBR.OLS2N, [2] TOLBR.OLS2P, [1] TOLBR.OLS1N, [0] TOLBR.OLS1P
0x88A38 MTU9
  [1] TBTM.TTSB, [0] TBTM.TTSA
0x88A39 MTU10
  [1] TBTM.TTSB, [0] TBTM.TTSA
0x88A40 MTU10 16-bit
  [15:14] TADCR.BF, [7] TADCR.UT4AE, [6] TADCR.DT4AE, [5] TADCR.UT4BE, [4] TADCR.DT4BE, [3] TADCR.ITA3AE, [2] TADCR.ITA4VE, [1] TADCR.ITB3AE, [0] TADCR.ITB4VE
0x88A60 MTUB
  [7] TWCR.CCE, [0] TWCR.WRE
0x88A80 MTUB
  [7] TSTR.CST4, [6] TSTR.CST3, [2] TSTR.CST2, [1] TSTR.CST1, [0] TSTR.CST0
0x88A81 MTUB
  [7] TSYR.SYNC4, [6] TSYR.SYNC3, [2] TSYR.SYNC2, [1] TSYR.SYNC1, [0] TSYR.SYNC0
0x88A84 MTUB
  [0] TRWER.RWE
0x88B00 MTU6
  [7:5] TCR.CCLR, [4:3] TCR.CKEG, [2:0] TCR.TPSC
0x88B01 MTU6
  [6] TMDR.BFE, [5] TMDR.BFB, [4] TMDR.BFA, [3:0] TMDR.MD
0x88B02 MTU6
  [7:4] TIORH.IOB, [3:0] TIORH.IOA
0x88B03 MTU6
  [7:4] TIORL.IOD, [3:0] TIORL.IOC
0x88B04 MTU6
  [7] TIER.TTGE, [4] TIER.TCIEV, [3] TIER.TGIED, [2] TIER.TGIEC, [1] TIER.TGIEB, [0] TIER.TGIEA
0x88B24 MTU6
  [1] TIER2.TGIEF, [0] TIER2.TGIEE
0x88B26 MTU6
  [2] TBTM.TTSE, [1] TBTM.TTSB, [0] TBTM.TTSA
0x88B80 MTU7
  [6:5] TCR.CCLR, [4:3] TCR.CKEG, [2:0] TCR.TPSC
0x88B81 MTU7
  [3:0] TMDR.MD
0x88B82 MTU7
  [7:4] TIOR.IOB, [3:0] TIOR.IOA
0x88B84 MTU7
  [7] TIER.TTGE, [5] TIER.TCIEU, [4] TIER.TCIEV, [1] TIER.TGIEB, [0] TIER.TGIEA
0x88B85 MTU7
  [7] TSR.TCFD
0x88B90 MTU7
  [3] TICCR.I2BE, [2] TICCR.I2AE, [1] TICCR.I1BE, [0] TICCR.I1AE
0x88C00 MTU8
  [6:5] TCR.CCLR, [4:3] TCR.CKEG, [2:0] TCR.TPSC
0x88C01 MTU8
  [3:0] TMDR.MD
0x88C02 MTU8
  [7:4] TIOR.IOB, [3:0] TIOR.IOA
0x88C04 MTU8
  [7] TIER.TTGE, [5] TIER.TCIEU, [4] TIER.TCIEV, [1] TIER.TGIEB, [0] TIER.TGIEA
0x88C05 MTU8
  [7] TSR.TCFD
0x88C84 MTU11
  [1:0] TCRU.TPSC
0x88C86 MTU11
  [4:0] TIORU.IOC
0x88C94 MTU11
  [1:0] TCRV.TPSC
0x88C96 MTU11
  [4:0] TIORV.IOC
0x88CA4 MTU11
  [1:0] TCRW.TPSC
0x88CA6 MTU11
  [4:0] TIORW.IOC
0x88CB2 MTU11
  [2] TIER.TGIE5U, [1] TIER.TGIE5V, [0] TIER.TGIE5W
0x88CB4 MTU11
  [2] TSTR.CSTU5, [1] TSTR.CSTV5, [0] TSTR.CSTW5
0x88CB6 MTU11
  [2] TCNTCMPCLR.CMPCLR5U, [1] TCNTCMPCLR.CMPCLR5V, [0] TCNTCMPCLR.CMPCLR5W
0x89000 S12AD
  [7] ADCSR.ADST, [6] ADCSR.ADCS, [4] ADCSR.ADIE, [3:2] ADCSR.CKS, [1] ADCSR.TRGE, [0] ADCSR.EXTRG
0x89004 S12AD 16-bit
  [7:0] ADANS.ANS
0x89008 S12AD 16-bit
  [7:0] ADADS.ADS
0x8900C S12AD
  [1:0] ADADC.ADC
0x8900E S12AD 16-bit
  [15] ADCER.ADRFMT, [5] ADCER.ACE
0x89010 S12AD
  [3:0] ADSTRGR.ADSTRS
0x8C000 PORT0
  [7] DDR.B7, [5] DDR.B5, [n] DDR.B{n} (n=0..3)
0x8C001 PORT1
  [n] DDR.B{n} (n=0..7)
0x8C002 PORT2
  [n] DDR.B{n} (n=0..7)
0x8C003 PORT3
  [n] DDR.B{n} (n=0..4)
{0x8C000+i} PORT{i} (i=4..7)
  [n] DDR.B{n} (n=0..7)
0x8C008 PORT8
  [n] DDR.B{n} (n=0..5)
0x8C009 PORT9
  [n] DDR.B{n} (n=0..7)
0x8C00A PORTA
  [n] DDR.B{n} (n=0..7)
0x8C00B PORTB
  [n] DDR.B{n} (n=0..7)
0x8C00C PORTC
  [n] DDR.B{n} (n=0..7)
0x8C00D PORTD
  [n] DDR.B{n} (n=0..7)
0x8C00E PORTE
  [n] DDR.B{n} (n=0..7)
0x8C00F PORTF
  [n] DDR.B{n} (n=0..4)
0x8C010 PORTG
  [n] DDR.B{n} (n=0..7)
0x8C020 PORT0
  [7] DR.B7, [5] DR.B5, [n] DR.B{n} (n=0..3)
0x8C021 PORT1
  [n] DR.B{n} (n=0..7)
0x8C022 PORT2
  [n] DR.B{n} (n=0..7)
0x8C023 PORT3
  [n] DR.B{n} (n=0..4)
0x8C024 PORT4
  [n] DR.B{n} (n=0..7)
0x8C025 PORT5
  [n] DR.B{n} (n=4..7), [2] DR.B2, [1] DR.B1, [0] DR.B0
0x8C026 PORT6
  [n] DR.B{n} (n=0..7)
0x8C027 PORT7
  [n] DR.B{n} (n=0..7)
0x8C028 PORT8
  [n] DR.B{n} (n=0..5)
0x8C029 PORT9
  [n] DR.B{n} (n=0..7)
0x8C02A PORTA
  [n] DR.B{n} (n=0..7)
0x8C02B PORTB
  [n] DR.B{n} (n=0..7)
0x8C02C PORTC
  [n] DR.B{n} (n=0..7)
0x8C02D PORTD
  [n] DR.B{n} (n=0..7)
0x8C02E PORTE
  [n] DR.B{n} (n=0..7)
0x8C02F PORTF
  [n] DR.B{n} (n=0..4)
0x8C030 PORTG
  [n] DR.B{n} (n=0..7)
0x8C040 PORT0
  [7] PORT.B7, [5] PORT.B5, [n] PORT.B{n} (n=0..3)
0x8C041 PORT1
  [n] PORT.B{n} (n=0..7)
0x8C042 PORT2
  [n] PORT.B{n} (n=0..7)
0x8C043 PORT3
  [n] PORT.B{n} (n=0..5)
{0x8C040+i} PORT{i} (i=4..7)
  [n] PORT.B{n} (n=0..7)
0x8C048 PORT8
  [n] PORT.B{n} (n=0..5)
0x8C049 PORT9
  [n] PORT.B{n} (n=0..7)
0x8C04A PORTA
  [n] PORT.B{n} (n=0..7)
0x8C04B PORTB
  [n] PORT.B{n} (n=0..7)
0x8C04C PORTC
  [n] PORT.B{n} (n=0..7)
0x8C04D PORTD
  [n] PORT.B{n} (n=0..7)
0x8C04E PORTE
  [n] PORT.B{n} (n=0..7)
0x8C04F PORTF
  [n] PORT.B{n} (n=0..4)
0x8C050 PORTG
  [n] PORT.B{n} (n=0..7)
0x8C060 PORT0
  [7] ICR.B7, [5] ICR.B5, [n] ICR.B{n} (n=0..3)
0x8C061 PORT1
  [n] ICR.B{n} (n=0..7)
0x8C062 PORT2
  [n] ICR.B{n} (n=0..7)
0x8C063 PORT3
  [n] ICR.B{n} (n=0..4)
{0x8C060+i} PORT{i} (i=4..7)
  [n] ICR.B{n} (n=0..7)
0x8C068 PORT8
  [n] ICR.B{n} (n=0..5)
0x8C069 PORT9
  [n] ICR.B{n} (n=0..7)
0x8C06A PORTA
  [n] ICR.B{n} (n=0..7)
0x8C06B PORTB
  [n] ICR.B{n} (n=0..7)
0x8C06C PORTC
  [n] ICR.B{n} (n=0..7)
0x8C06D PORTD
  [n] ICR.B{n} (n=0..7)
0x8C06E PORTE
  [n] ICR.B{n} (n=0..7)
0x8C06F PORTF
  [n] ICR.B{n} (n=0..4)
0x8C070 PORTG
  [n] ICR.B{n} (n=0..7)
0x8C080 PORT0
  [7] ODR.B7, [5] ODR.B5, [n] ODR.B{n} (n=0..3)
0x8C081 PORT1
  [n] ODR.B{n} (n=0..7)
0x8C082 PORT2
  [n] ODR.B{n} (n=0..7)
0x8C083 PORT3
  [n] ODR.B{n} (n=0..4)
0x8C08C PORTC
  [n] ODR.B{n} (n=0..7)
0x8C0C9 PORT9
  [n] PCR.B{n} (n=0..7)
0x8C0CA PORTA
  [n] PCR.B{n} (n=0..7)
0x8C0CB PORTB
  [n] PCR.B{n} (n=0..7)
0x8C0CC PORTC
  [n] PCR.B{n} (n=0..7)
0x8C0CD PORTD
  [n] PCR.B{n} (n=0..7)
0x8C0CE PORTE
  [n] PCR.B{n} (n=0..7)
0x8C0D0 PORTG
  [n] PCR.B{n} (n=0..7)
0x8C100 IOPORT
  [n] PF0CSE.CS{n}E (n=0..7)
0x8C101 IOPORT
  [2n-7:2n-8] PF1CSS.CS{n}S (n=4..7)
0x8C102 IOPORT
  [7:6] PF2CSS.CS3S, [5:4] PF2CSS.CS2S, [3:2] PF2CSS.CS1S, [0] PF2CSS.CS0S
0x8C103 IOPORT
  [n-16] PF3BUS.A{n}E (n=16..23)
0x8C104 IOPORT
  [n-8] PF4BUS.A{n}E (n=10..15), [1:0] PF4BUS.ADRLE
0x8C105 IOPORT
  [7] PF5BUS.WR32BC32E, [6] PF5BUS.WR1BC1E, [5] PF5BUS.DH32E, [4] PF5BUS.DHE, [1] PF5BUS.ADRHMS
0x8C106 IOPORT
  [7] PF6BUS.SDCLKE, [6] PF6BUS.DQM1E, [4] PF6BUS.MDSDE, [1:0] PF6BUS.WAITS
0x8C107 IOPORT
  [7:6] PF7DMA.EDMA1S, [5:4] PF7DMA.EDMA0S
0x8C108 IOPORT
  [7] PF8IRQ.ITS15, [5] PF8IRQ.ITS13, [n-8] PF8IRQ.ITS{n} (n=8..11)
0x8C109 IOPORT
  [n] PF9IRQ.ITS{n} (n=0..7)
0x8C10A IOPORT
  [0] PFAADC.ADTRG0S
0x8C10B IOPORT
  [n] PFBTMR.TMR{n}S (n=0..3)
0x8C10C IOPORT
  [7] PFCMTU.TCLKS, [n] PFCMTU.MTUS{n} (n=2..6)
0x8C10D IOPORT
  [7] PFDMTU.TCLKS, [6] PFDMTU.MTUS6
0x8C10E IOPORT
  [7] PFENET.EE, [4] PFENET.PHYMODE, [n] PFENET.ENETE{n} (n=0..3)
0x8C10F IOPORT
  [6] PFFSCI.SCI6S, [3] PFFSCI.SCI3S, [2] PFFSCI.SCI2S, [1] PFFSCI.SCI1S
0x8C110 IOPORT
  [n+4] PFGSPI.SSL{n}E (n=0..3), [3] PFGSPI.MISOE, [2] PFGSPI.MOSIE, [1] PFGSPI.RSPCKE, [0] PFGSPI.RSPIS
0x8C111 IOPORT
  [n+4] PFHSPI.SSL{n}E (n=0..3), [3] PFHSPI.MISOE, [2] PFHSPI.MOSIE, [1] PFHSPI.RSPCKE, [0] PFHSPI.RSPIS
0x8C113 IOPORT
  [0] PFJCAN.CAN0E
0x8C114 IOPORT
  [4] PFKUSB.USBE, [3] PFKUSB.PDHZS, [2] PFKUSB.PUPHZS, [1:0] PFKUSB.USBMD
0x8C115 IOPORT
  [4] PFLUSB.USBE, [3] PFLUSB.PDHZS, [2] PFLUSB.PUPHZS, [1:0] PFLUSB.USBMD
0x8C116 IOPORT
  [n] PFMPOE.POE{n}E (n=0..7)
0x8C117 IOPORT
  [1] PFNPOE.POE9E, [0] PFNPOE.POE8E
0x8C280 SYSTEM
  [7] DPSBYCR.DPSBY, [6] DPSBYCR.IOKEEP, [5] DPSBYCR.RAMCUT2, [4] DPSBYCR.RAMCUT1, [0] DPSBYCR.RAMCUT0
0x8C281 SYSTEM
  [5:0] DPSWCR.WTSTS
0x8C282 SYSTEM
  [7] DPSIER.DNMIE, [6] DPSIER.DUSBE, [5] DPSIER.DRTCE, [4] DPSIER.DLVDE, [n] DPSIER.DIRQ{n}E (n=0..3)
0x8C283 SYSTEM
  [7] DPSIFR.DNMIF, [6] DPSIFR.DUSBF, [5] DPSIFR.DRTCF, [4] DPSIFR.DLVDF, [n] DPSIFR.DIRQ{n}F (n=0..3)
0x8C284 SYSTEM
  [7] DPSIEGR.DNMIEG, [n] DPSIEGR.DIRQ{n}EG (n=0..3)
